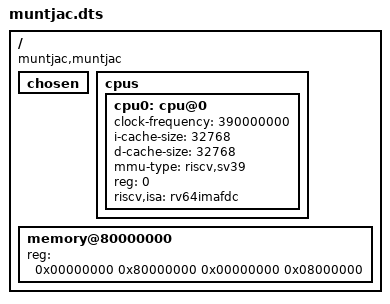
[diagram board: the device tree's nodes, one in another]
/dts-v1/;
/ {
    #address-cells = <2>;
    #size-cells = <2>;
    compatible = "muntjac,muntjac";

    chosen {
    };

    cpus {
        #address-cells = <1>;
        #size-cells = <0>;
        cpu0: cpu@0 {
            device_type = "cpu";
            clock-frequency = <390000000>;
            /* Verify this */
            i-cache-size = <32768>;
            /* Verify this */
            d-cache-size = <32768>;
            mmu-type = "riscv,sv39";
            reg = <0>;
            riscv,isa = "rv64imafdc";
            status = "okay";
        };
    };

    memory@80000000 {
        device_type = "memory";
        reg = <0x00000000 0x80000000 0x00000000 0x08000000>;
    };

};
